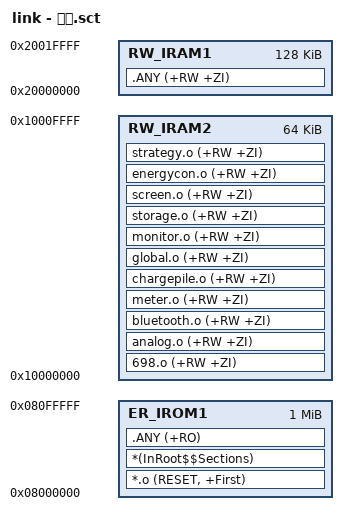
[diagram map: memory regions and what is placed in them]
; *************************************************************
; *** Scatter-Loading Description File generated by uVision ***
; *************************************************************

LR_IROM1 0x08000000 0x00100000  {    ; load region size_region
  ER_IROM1 0x08000000 0x00100000  {  ; load address = execution address
   *.o (RESET, +First)
   *(InRoot$$Sections)
   .ANY (+RO)
  }
  
  RW_IRAM2 0x10000000 0x00010000  {  ; RW data
   698.o (+RW +ZI)
   analog.o (+RW +ZI)
   bluetooth.o (+RW +ZI)
   meter.o (+RW +ZI)
   chargepile.o (+RW +ZI)
   global.o (+RW +ZI)
   monitor.o (+RW +ZI)
   storage.o (+RW +ZI)
   screen.o (+RW +ZI)
   energycon.o (+RW +ZI)
   strategy.o (+RW +ZI)
  }
  
  RW_IRAM1 0x20000000 0x00020000  {  ; RW data
   .ANY (+RW +ZI)
  }

}

